AUTOSAR XML (schema 4-0-3)
standard types defined: boolean, float32, float64, sint16, sint32, sint8, uint16, uint32, uint8
package /ApplDataTypes
  app type AccelLevel: category=VALUE
  app type BrakeEvent: category=VALUE
  app type Speedo: category=VALUE
package /ImplDataTypes
  impl type AccelLevel: category=VALUE, base-type=uint8
  impl type BrakeEvent: category=VALUE, base-type=boolean
  impl type Speedo: category=VALUE, base-type=uint32
package /Interfaces
  4 x sender receiver interface:
    BrakeState
      data BrakeEvent: type=BrakeEvent
    LevelToCALL
      data LevelToCALL: type=AccelLevel
    LevelToEC
      data LevelToEC: type=AccelLevel
    SpeedoValue
      data SpeedoValue: type=Speedo
package /SpeedoMeter
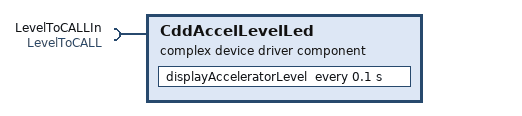
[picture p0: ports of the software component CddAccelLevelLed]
  complex device driver sw component type CddAccelLevelLed
    require port LevelToCALLIn: nonqueued-receiver-com-spec{data-element=LevelToCALL, init-value=Value:0}, required-interface=LevelToCALL
    behavior IB_CALL: data-type-mapping=SM_DTM, handle-termination-and-restart=NO-SUPPORT
      timing event TimingEventCALL: start-on-event=displayAcceleratorLevel, period=0.1
      runnable displayAcceleratorLevel
        data-receive-point-by-arguments:
          access VariableAccess: accessed-variable=LevelToCALLIn.LevelToCALL
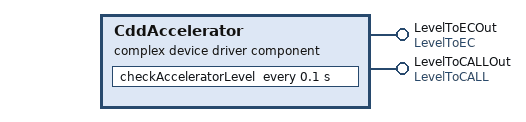
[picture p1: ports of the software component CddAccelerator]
  complex device driver sw component type CddAccelerator
    provide port LevelToECOut: provided-interface=LevelToEC
    provide port LevelToCALLOut: provided-interface=LevelToCALL
    behavior IB_CA: data-type-mapping=SM_DTM, handle-termination-and-restart=NO-SUPPORT
      timing event TimingEventCA: start-on-event=checkAcceleratorLevel, period=0.1
      runnable checkAcceleratorLevel
        data-send-points:
          access VariableAccess: accessed-variable=LevelToECOut.LevelToEC
          access VariableAccess1: accessed-variable=LevelToCALLOut.LevelToCALL
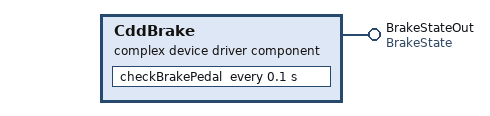
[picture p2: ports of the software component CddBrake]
  complex device driver sw component type CddBrake
    provide port BrakeStateOut: provided-interface=BrakeState
    behavior IB_CB: data-type-mapping=SM_DTM, handle-termination-and-restart=NO-SUPPORT
      timing event TimingEventCB: start-on-event=checkBrakePedal, period=0.1
      runnable checkBrakePedal
        data-send-points:
          access VariableAccess: accessed-variable=BrakeStateOut.BrakeEvent
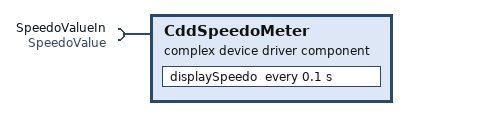
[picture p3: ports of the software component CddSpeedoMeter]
  complex device driver sw component type CddSpeedoMeter
    require port SpeedoValueIn: nonqueued-receiver-com-spec{data-element=SpeedoValue, init-value=Value:0}, required-interface=SpeedoValue
    behavior IB_CSM: data-type-mapping=SM_DTM, handle-termination-and-restart=NO-SUPPORT
      timing event TimingEventCSM: start-on-event=displaySpeedo, period=0.1
      runnable displaySpeedo
        data-receive-point-by-arguments:
          access VariableAccess: accessed-variable=SpeedoValueIn.SpeedoValue
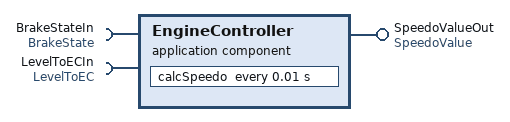
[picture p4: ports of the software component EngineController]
  application sw component type EngineController
    require port BrakeStateIn: nonqueued-receiver-com-spec{data-element=BrakeEvent, init-value=Value:0}, required-interface=BrakeState
    require port LevelToECIn: nonqueued-receiver-com-spec{data-element=LevelToEC, init-value=Value:0}, required-interface=LevelToEC
    provide port SpeedoValueOut: provided-interface=SpeedoValue
    behavior IB_EC: data-type-mapping=SM_DTM, handle-termination-and-restart=NO-SUPPORT
      timing event TimingEventEC: start-on-event=calcSpeedo, period=0.01
      runnable calcSpeedo
        data-receive-point-by-arguments:
          access VariableAccess: accessed-variable=BrakeStateIn.BrakeEvent
          access VariableAccess1: accessed-variable=LevelToECIn.LevelToEC
        data-send-points:
          access VariableAccess2: accessed-variable=SpeedoValueOut.SpeedoValue
  composition sw component type SMTopLevel
    5 x component:
      EngineController: type=EngineController
      CddBrake: type=CddBrake
      CddAccelerator: type=CddAccelerator
      CddAccelLevelLed: type=CddAccelLevelLed
      CddSpeedoMeter: type=CddSpeedoMeter
    connect CddAccelerator.LevelToCALLOut -> CddAccelLevelLed.LevelToCALLIn
    connect EngineController.SpeedoValueOut -> CddSpeedoMeter.SpeedoValueIn
    connect CddAccelerator.LevelToECOut -> EngineController.LevelToECIn
    connect CddBrake.BrakeStateOut -> EngineController.BrakeStateIn
  data type mapping set SM_DTM
    data-type-maps:
      application-data-type=AccelLevel, implementation-data-type=AccelLevel
      application-data-type=BrakeEvent, implementation-data-type=BrakeEvent
      application-data-type=Speedo, implementation-data-type=Speedo
package /System
  ecuc value collection EcucValueCollection: ecu-extract=SystemSM, ecuc-values=[Os, Rte]
  system SystemSM: system-version=1.0.0
    system mapping DummySystemMapping
    root-software-compositions:
      root sw composition prototype RootSwCompositionPrototype: software-composition=SMTopLevel
